# CY8C5888LTI_LP097 register map
File version: 0.1
CY8C58LP
Registers are 8-bit, read-write, no defined reset value unless marked. A register's access mark holds for its fields unless they carry their own. Offsets are from the block's base; lines under a group give offsets from that group; [hi:lo] are bit positions; {n}, {i} and the like mark numbered series; 'fields as' and 'values as' point back to an identical list; <NAME> marks a mode.

## Memory map
0x00000000 UART_1 — UART
0x00000000 Timer_1

## UART_1 — UART
Base 0x00000000
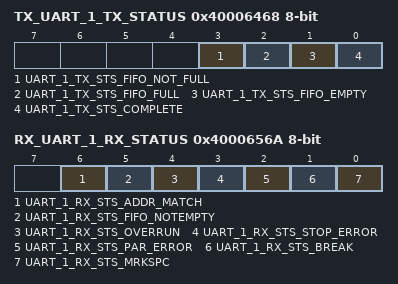
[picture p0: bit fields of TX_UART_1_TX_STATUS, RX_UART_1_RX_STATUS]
0x40006468 TX_UART_1_TX_STATUS — TX status register
  [3] UART_1_TX_STS_FIFO_NOT_FULL ro, [2] UART_1_TX_STS_FIFO_FULL ro, [1] UART_1_TX_STS_FIFO_EMPTY ro, [0] UART_1_TX_STS_COMPLETE ro
0x40006529 RX_UART_1_RX_ADDRESS1 — RX Address1 Register
0x40006539 RX_UART_1_RX_ADDRESS2 — RX Address2 Register
0x40006548 TX_UART_1_TX_DATA — TX Data Register
0x40006549 RX_UART_1_RX_DATA — RX Data Register
0x4000656A RX_UART_1_RX_STATUS — RX status register
  [6] UART_1_RX_STS_ADDR_MATCH ro, [5] UART_1_RX_STS_FIFO_NOTEMPTY ro, [4] UART_1_RX_STS_OVERRUN ro, [3] UART_1_RX_STS_STOP_ERROR ro, [2] UART_1_RX_STS_PAR_ERROR ro, [1] UART_1_RX_STS_BREAK ro, [0] UART_1_RX_STS_MRKSPC ro

## Timer_1
Base 0x00000000
0x40006408 Timer_1_COUNTER 16-bit — UDB.A0 - Current Down Counter Value
0x40006428 Timer_1_PERIOD 16-bit — UDB.D0 - Assigned Period
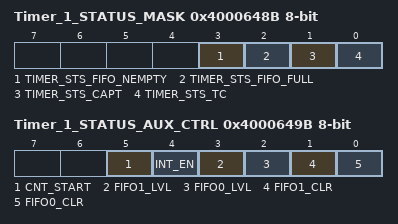
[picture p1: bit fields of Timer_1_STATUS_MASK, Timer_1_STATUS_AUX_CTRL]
0x4000648B Timer_1_STATUS_MASK — UDB Status bits Interrupt Mask Enable Register
  [3] TIMER_STS_FIFO_NEMPTY ro — FIFO Empty status
  [2] TIMER_STS_FIFO_FULL ro — FIFO Full Status
  [1] TIMER_STS_CAPT ro — Enables the Interrupt on Capture
  [0] TIMER_STS_TC ro — Enables the Interrupt on TC
0x4000649B Timer_1_STATUS_AUX_CTRL — UDB Auxilliary Control Register
  [5] CNT_START — FIFO0 clear
    0=E_CNT_START0 (Disable counter); 1=E_CNT_START1 (Enable counter)
  [4] INT_EN
    0=E_INT_EN0 (Interrupt disabled); 1=E_INT_EN1 (Interrupt enabled)
  [3] FIFO1_LVL — FIFO level
    0=E_FIFO_LVL_0 (FIFO LVL: input mode: FIFO not full; output mode: FIFO not empty); 1=E_FIFO_LVL_1 (FIFO LVL: input mode: FIFO at least 1/2 empty; output mode: FIFO at least 1/2 full)
  [2] FIFO0_LVL — FIFO level
    values as FIFO1_LVL
  [1] FIFO1_CLR — FIFO1 clear
    0=E_FIFO_CLR_0 (Normal FIFO operation); 1=E_FIFO_CLR_1 (Clear FIFO state)
  [0] FIFO0_CLR — FIFO0 clear
    values as FIFO1_CLR
